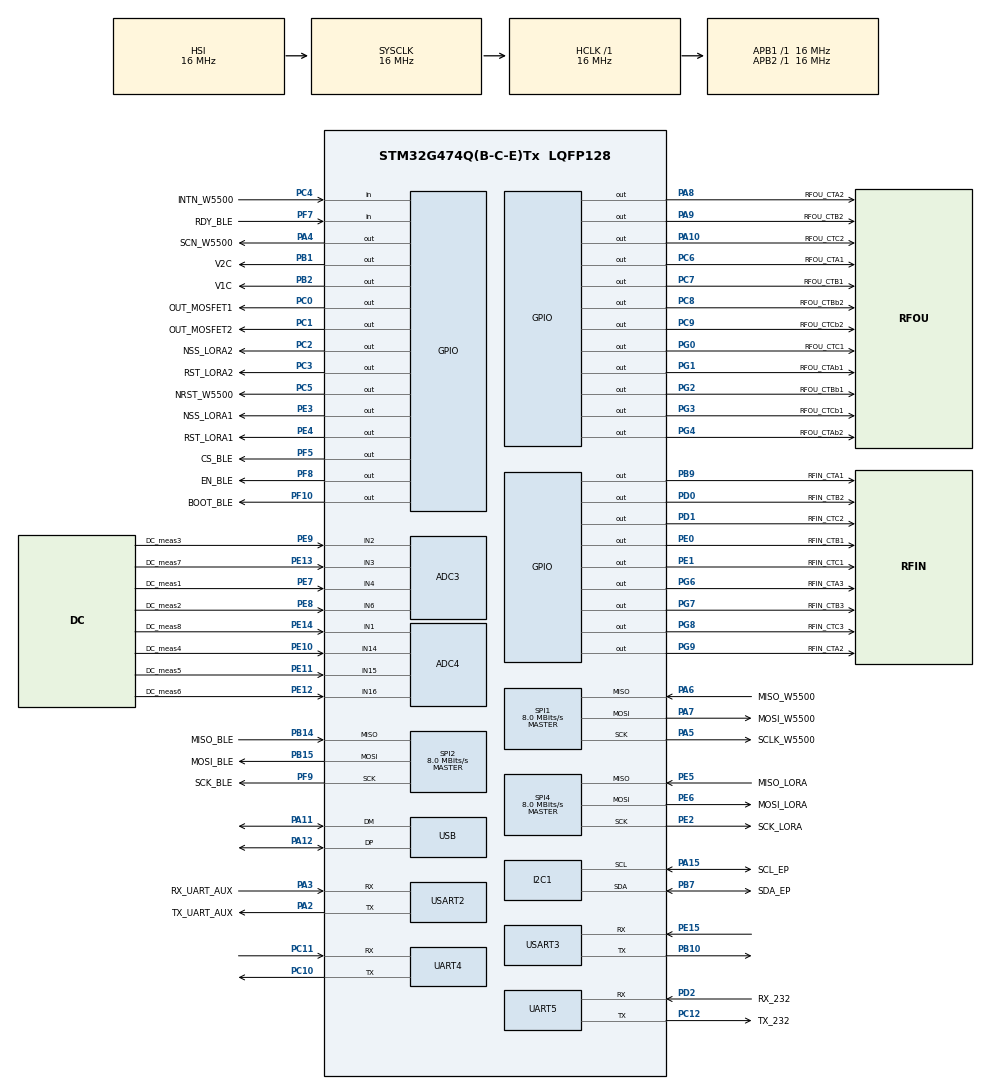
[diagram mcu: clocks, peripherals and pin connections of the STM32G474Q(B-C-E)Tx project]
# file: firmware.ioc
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ADC3.Channel-0\#ChannelRegularConversion=ADC_CHANNEL_4
ADC3.NbrOfConversionFlag=1
ADC3.OffsetNumber-0\#ChannelRegularConversion=ADC_OFFSET_NONE
ADC3.Rank-0\#ChannelRegularConversion=1
ADC3.SamplingTime-0\#ChannelRegularConversion=ADC_SAMPLETIME_2CYCLES_5
ADC3.master=1
ADC4.Channel-0\#ChannelRegularConversion=ADC_CHANNEL_1
ADC4.NbrOfConversionFlag=1
ADC4.OffsetNumber-0\#ChannelRegularConversion=ADC_OFFSET_NONE
ADC4.Rank-0\#ChannelRegularConversion=1
ADC4.SamplingTime-0\#ChannelRegularConversion=ADC_SAMPLETIME_2CYCLES_5
I2C1.Timing=0x00503D58
Mcu.Family=STM32G4
Mcu.Name=STM32G474Q(B-C-E)Tx
Mcu.Package=LQFP128
NVIC.PriorityGroup=NVIC_PRIORITYGROUP_4
NVIC.UART4_IRQn=true\:0\:0\:false\:false\:true\:true\:true\:true
NVIC.UART5_IRQn=true\:0\:0\:false\:false\:true\:true\:true\:true
NVIC.USART2_IRQn=true\:0\:0\:false\:false\:true\:true\:true\:true
NVIC.USART3_IRQn=true\:0\:0\:false\:false\:true\:true\:true\:true
NVIC.USB_LP_IRQn=true\:0\:0\:false\:false\:true\:false\:true\:true
PA10.GPIO_Label=RFOU_CTC2
PA10.Signal=GPIO_Output
PA11.Mode=Device
PA11.Signal=USB_DM
PA12.Mode=Device
PA12.Signal=USB_DP
PA15.GPIO_Label=SCL_EP
PA15.Mode=I2C
PA15.Signal=I2C1_SCL
PA2.GPIO_Label=TX_UART_AUX
PA2.Mode=Asynchronous
PA2.Signal=USART2_TX
PA3.GPIO_Label=RX_UART_AUX
PA3.Mode=Asynchronous
PA3.Signal=USART2_RX
PA4.GPIO_Label=SCN_W5500
PA4.Signal=GPIO_Output
PA5.GPIO_Label=SCLK_W5500
PA5.Mode=Full_Duplex_Master
PA5.Signal=SPI1_SCK
PA6.GPIO_Label=MISO_W5500
PA6.Mode=Full_Duplex_Master
PA6.Signal=SPI1_MISO
PA7.GPIO_Label=MOSI_W5500
PA7.Mode=Full_Duplex_Master
PA7.Signal=SPI1_MOSI
PA8.GPIO_Label=RFOU_CTA2
PA8.Signal=GPIO_Output
PA9.GPIO_Label=RFOU_CTB2
PA9.Signal=GPIO_Output
PB1.GPIO_Label=V2C
PB1.Signal=GPIO_Output
PB10.Mode=Asynchronous
PB10.Signal=USART3_TX
PB14.GPIO_Label=MISO_BLE
PB14.Mode=Full_Duplex_Master
PB14.Signal=SPI2_MISO
PB15.GPIO_Label=MOSI_BLE
PB15.Mode=Full_Duplex_Master
PB15.Signal=SPI2_MOSI
PB2.GPIO_Label=V1C
PB2.Signal=GPIO_Output
PB7.GPIO_Label=SDA_EP
PB7.Mode=I2C
PB7.Signal=I2C1_SDA
PB9.GPIO_Label=RFIN_CTA1
PB9.Signal=GPIO_Output
PC0.GPIO_Label=OUT_MOSFET1
PC0.Signal=GPIO_Output
PC1.GPIO_Label=OUT_MOSFET2
PC1.Signal=GPIO_Output
PC10.Mode=Asynchronous
PC10.Signal=UART4_TX
PC11.Mode=Asynchronous
PC11.Signal=UART4_RX
PC12.GPIO_Label=TX_232
PC12.Mode=Asynchronous
PC12.Signal=UART5_TX
PC2.GPIO_Label=NSS_LORA2
PC2.Signal=GPIO_Output
PC3.GPIO_Label=RST_LORA2
PC3.Signal=GPIO_Output
PC4.GPIO_Label=INTN_W5500
PC4.Signal=GPIO_Input
PC5.GPIO_Label=NRST_W5500
PC5.Signal=GPIO_Output
PC6.GPIO_Label=RFOU_CTA1
PC6.Signal=GPIO_Output
PC7.GPIO_Label=RFOU_CTB1
PC7.Signal=GPIO_Output
PC8.GPIO_Label=RFOU_CTBb2
PC8.Signal=GPIO_Output
PC9.GPIO_Label=RFOU_CTCb2
PC9.Signal=GPIO_Output
PD0.GPIO_Label=RFIN_CTB2
PD0.Signal=GPIO_Output
PD1.GPIO_Label=RFIN_CTC2
PD1.Signal=GPIO_Output
PD2.GPIO_Label=RX_232
PD2.Mode=Asynchronous
PD2.Signal=UART5_RX
PE0.GPIO_Label=RFIN_CTB1
PE0.Signal=GPIO_Output
PE1.GPIO_Label=RFIN_CTC1
PE1.Signal=GPIO_Output
PE10.GPIO_Label=DC_meas4
PE10.Signal=SharedAnalog_PE10
PE11.GPIO_Label=DC_meas5
PE11.Signal=SharedAnalog_PE11
PE12.GPIO_Label=DC_meas6
PE12.Signal=SharedAnalog_PE12
PE13.GPIO_Label=DC_meas7
PE13.Signal=SharedAnalog_PE13
PE14.GPIO_Label=DC_meas8
PE14.Signal=SharedAnalog_PE14
PE15.Mode=Asynchronous
PE15.Signal=USART3_RX
PE2.GPIO_Label=SCK_LORA
PE2.Mode=Full_Duplex_Master
PE2.Signal=SPI4_SCK
PE3.GPIO_Label=NSS_LORA1
PE3.Signal=GPIO_Output
PE4.GPIO_Label=RST_LORA1
PE4.Signal=GPIO_Output
PE5.GPIO_Label=MISO_LORA
PE5.Mode=Full_Duplex_Master
PE5.Signal=SPI4_MISO
PE6.GPIO_Label=MOSI_LORA
PE6.Mode=Full_Duplex_Master
PE6.Signal=SPI4_MOSI
PE7.GPIO_Label=DC_meas1
PE7.Signal=SharedAnalog_PE7
PE8.GPIO_Label=DC_meas2
PE8.Signal=SharedAnalog_PE8
PE9.GPIO_Label=DC_meas3
PE9.Signal=SharedAnalog_PE9
PF10.GPIO_Label=BOOT_BLE
PF10.Signal=GPIO_Output
PF5.GPIO_Label=CS_BLE
PF5.Signal=GPIO_Output
PF7.GPIO_Label=RDY_BLE
PF7.Signal=GPIO_Input
PF8.GPIO_Label=EN_BLE
PF8.Signal=GPIO_Output
PF9.GPIO_Label=SCK_BLE
PF9.Mode=Full_Duplex_Master
PF9.Signal=SPI2_SCK
PG0.GPIO_Label=RFOU_CTC1
PG0.Signal=GPIO_Output
PG1.GPIO_Label=RFOU_CTAb1
PG1.Signal=GPIO_Output
PG2.GPIO_Label=RFOU_CTBb1
PG2.Signal=GPIO_Output
PG3.GPIO_Label=RFOU_CTCb1
PG3.Signal=GPIO_Output
PG4.GPIO_Label=RFOU_CTAb2
PG4.Signal=GPIO_Output
PG6.GPIO_Label=RFIN_CTA3
PG6.Signal=GPIO_Output
PG7.GPIO_Label=RFIN_CTB3
PG7.Signal=GPIO_Output
PG8.GPIO_Label=RFIN_CTC3
PG8.Signal=GPIO_Output
PG9.GPIO_Label=RFIN_CTA2
PG9.Signal=GPIO_Output
ProjectManager.HeapSize=0x200
ProjectManager.StackSize=0x400
ProjectManager.TargetToolchain=CMake
RCC.AHBFreq_Value=16000000
RCC.APB1Freq_Value=16000000
RCC.APB1TimFreq_Value=16000000
RCC.APB2Freq_Value=16000000
RCC.APB2TimFreq_Value=16000000
RCC.CortexFreq_Value=16000000
RCC.EXTERNAL_CLOCK_VALUE=12288000
RCC.HCLKFreq_Value=16000000
RCC.HSE_VALUE=8000000
RCC.HSI48_VALUE=48000000
RCC.HSI_VALUE=16000000
RCC.LSE_VALUE=32768
RCC.PLLN=12
RCC.PLLQ=RCC_PLLQ_DIV4
RCC.SYSCLKFreq_VALUE=16000000
RCC.USBFreq_Value=48000000
RCC.VCOOutputFreq_Value=192000000
SH.SharedAnalog_PE10.0=GPIO_Analog
SH.SharedAnalog_PE10.1=ADC4_IN14,IN14-Single-Ended
SH.SharedAnalog_PE11.0=GPIO_Analog
SH.SharedAnalog_PE11.1=ADC4_IN15,IN15-Single-Ended
SH.SharedAnalog_PE12.0=GPIO_Analog
SH.SharedAnalog_PE12.1=ADC4_IN16,IN16-Single-Ended
SH.SharedAnalog_PE13.0=GPIO_Analog
SH.SharedAnalog_PE13.1=ADC3_IN3,IN3-Single-Ended
SH.SharedAnalog_PE14.0=GPIO_Analog
SH.SharedAnalog_PE14.1=ADC4_IN1,IN1-Single-Ended
SH.SharedAnalog_PE7.0=GPIO_Analog
SH.SharedAnalog_PE7.1=ADC3_IN4,IN4-Single-Ended
SH.SharedAnalog_PE8.0=GPIO_Analog
SH.SharedAnalog_PE8.1=ADC3_IN6,IN6-Single-Ended
SH.SharedAnalog_PE9.0=GPIO_Analog
SH.SharedAnalog_PE9.1=ADC3_IN2,IN2-Single-Ended
SPI1.CalculateBaudRate=8.0 MBits/s
SPI1.Direction=SPI_DIRECTION_2LINES
SPI1.Mode=SPI_MODE_MASTER
SPI1.VirtualType=VM_MASTER
SPI2.CalculateBaudRate=8.0 MBits/s
SPI2.Direction=SPI_DIRECTION_2LINES
SPI2.Mode=SPI_MODE_MASTER
SPI2.VirtualType=VM_MASTER
SPI4.CalculateBaudRate=8.0 MBits/s
SPI4.Direction=SPI_DIRECTION_2LINES
SPI4.Mode=SPI_MODE_MASTER
SPI4.VirtualType=VM_MASTER
USART2.VirtualMode-Asynchronous=VM_ASYNC
USART3.VirtualMode-Asynchronous=VM_ASYNC
USB_DEVICE.CLASS_NAME_FS=CDC
USB_DEVICE.VirtualMode=Cdc
USB_DEVICE.VirtualModeFS=Cdc_FS
VP_SYS_VS_DBSignals.Mode=DisableDeadBatterySignals
VP_USB_DEVICE_VS_USB_DEVICE_CDC_FS.Mode=CDC_FS
board=custom

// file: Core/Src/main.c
/* USER CODE BEGIN Header */
/**
  ******************************************************************************
  * @file           : main.c
  * @brief          : Main program body
  ******************************************************************************
  * @attention
  *
  * Copyright (c) 2026 STMicroelectronics.
  * All rights reserved.
  *
  * This software is licensed under terms that can be found in the LICENSE file
  * in the root directory of this software component.
  * If no LICENSE file comes with this software, it is provided AS-IS.
  *
  ******************************************************************************
  */
/* USER CODE END Header */
#include "main.h"
#include "adc.h"
#include "i2c.h"
#include "spi.h"
#include "usart.h"
#include "usb_device.h"
#include "gpio.h"

/* USER CODE BEGIN Includes */
#include <string.h>   /* strlen() para los mensajes */
/* USER CODE END Includes */

/* USER CODE BEGIN PD */

/* W5500 Network Configuration */
#define W5500_SOCKET        0

/* MAC Address: 02:00:00:00:00:01 */
#define W5500_MAC0          0x02
#define W5500_MAC1          0x00
#define W5500_MAC2          0x00
#define W5500_MAC3          0x00
#define W5500_MAC4          0x00
#define W5500_MAC5          0x01

/* Static IP: 192.168.1.50 */
#define W5500_IP0           192
#define W5500_IP1           168
#define W5500_IP2           1
#define W5500_IP3           50

/* Subnet Mask: 255.255.255.0 */
#define W5500_SN0           255
#define W5500_SN1           255
#define W5500_SN2           255
#define W5500_SN3           0

/* Gateway: 192.168.1.1 */
#define W5500_GW0           192
#define W5500_GW1           168
#define W5500_GW2           1
#define W5500_GW3           1

/* PC / Destination IP: 192.168.1.10 */
#define PC_IP0              192
#define PC_IP1              168
#define PC_IP2              1
#define PC_IP3              10

#define UDP_PORT            5000
#define TX_INTERVAL_MS      10000   /* envio de "KA" cada 10 segundos */

/* USER CODE END PD */

/* USER CODE BEGIN PV */
/* Variables de estado (se leen por SWD con STM32_Programmer para depurar) */
volatile uint8_t  g_ver      = 0;   /* VERSIONR: debe ser 0x04 */
volatile uint8_t  g_phy      = 0;   /* PHYCFGR: link / velocidad / duplex */
volatile uint8_t  g_socket   = 0;   /* estado del socket (0x22 = UDP) */
volatile uint8_t  g_snmr     = 0;   /* protocolo del socket (0x02 = UDP) */
volatile uint8_t  g_phy_live = 0;   /* PHYCFGR leido en el bucle */
volatile uint16_t g_rsr      = 0;   /* bytes recibidos pendientes */
volatile uint16_t g_tx_count = 0;   /* mensajes enviados */
volatile uint16_t g_rx_count = 0;   /* mensajes recibidos */
/* USER CODE END PV */

void SystemClock_Config(void);

/* USER CODE BEGIN 0 */

/* ------------------------------------------------------------------
 * W5500: bloques de registros
 * ------------------------------------------------------------------ */
#define COMMON_BLOCK   0x00      /* registros comunes (MAC, IP, PHY...) */
#define SOCK0_BLOCK    0x01      /* registros del socket 0 */
#define SOCK0_TXBUF    0x02      /* buffer de transmision del socket 0 */
#define SOCK0_RXBUF    0x03      /* buffer de recepcion del socket 0 */

/* Registros comunes (bloque 0) */
#define MR             0x0000    /* modo */
#define SHAR           0x0009    /* direccion MAC (6 bytes) */
#define GAR            0x0001    /* gateway (4 bytes) */
#define SUBR           0x0005    /* mascara de subred (4 bytes) */
#define SIPR           0x000F    /* IP local (4 bytes) */
#define PHYCFGR        0x002E    /* configuracion del PHY */
#define VERSIONR       0x0039    /* version del chip (debe leer 0x04) */

/* Registros del socket 0 */
#define Sn_MR          0x0000    /* protocolo (0x02 = UDP) */
#define Sn_CR          0x0001    /* comando */
#define Sn_SR          0x0003    /* estado */
#define Sn_PORT        0x0004    /* puerto local (2 bytes) */
#define Sn_DIPR        0x000C    /* IP destino (4 bytes) */
#define Sn_DPORT       0x0010    /* puerto destino (2 bytes) */
#define Sn_RXBUF_SIZE  0x001E    /* tamanio del buffer RX (en KB) */
#define Sn_TXBUF_SIZE  0x001F    /* tamanio del buffer TX (en KB) */
#define Sn_TX_FSR      0x0020    /* espacio libre en TX */
#define Sn_TX_WR       0x0024    /* puntero de escritura de TX */
#define Sn_RX_RSR      0x0026    /* bytes recibidos pendientes */
#define Sn_RX_RD       0x0028    /* puntero de lectura de RX */

/* Comandos (Sn_CR) */
#define CR_OPEN        0x01      /* abrir socket */
#define CR_SEND        0x20      /* enviar */
#define CR_RECV        0x40      /* confirmar recepcion */

/* Estado del socket */
#define SOCK_UDP       0x22      /* socket abierto en modo UDP */

/* ------- Funciones de bajo nivel (SPI) ------- */
static void     w5500_hw_reset(void);
static void     w5500_write_reg(uint16_t addr, uint8_t block, uint8_t data);
static uint8_t  w5500_read_reg(uint16_t addr, uint8_t block);
static void     w5500_write_reg16(uint16_t addr, uint8_t block, uint16_t val);
static uint16_t w5500_read_reg16(uint16_t addr, uint8_t block);
static void     w5500_write_buf(uint8_t block, uint16_t addr, uint8_t* data, uint16_t len);
static void     w5500_read_buf(uint8_t block, uint16_t addr, uint8_t* data, uint16_t len);

/* ------- Funciones de aplicacion ------- */
static void udp_send(const char* msg);   /* envia un mensaje UDP al destino actual */

/* USER CODE END 0 */

int main(void)
{

  /* MCU Configuration--------------------------------------------------------*/

  /* Reset of all peripherals, Initializes the Flash interface and the Systick. */
  HAL_Init();

  /* Configure the system clock */
  SystemClock_Config();

  /* Initialize all configured peripherals */
  MX_GPIO_Init();
  MX_UART5_Init();
  MX_USART2_UART_Init();
  MX_ADC3_Init();
  MX_ADC4_Init();
  MX_I2C1_Init();
  MX_SPI1_Init();
  MX_SPI2_Init();
  MX_SPI4_Init();
  MX_UART4_Init();
  MX_USART3_UART_Init();
  /* USB CDC deshabilitado durante debug (colgaba en ISR USB_LP). Se usa SWD. */
  /* MX_USB_Device_Init(); */
  /* USER CODE BEGIN 2 */

  /* ================================================================
   * 1. Reset del W5500 y verificacion del chip
   * ================================================================ */
  w5500_hw_reset();                          /* reset por el pin NRST */
  w5500_write_reg(MR, COMMON_BLOCK, 0x80);   /* reset por software */
  HAL_Delay(100);
  w5500_write_reg(MR, COMMON_BLOCK, 0x00);   /* modo normal */

  g_ver = w5500_read_reg(VERSIONR, COMMON_BLOCK);
  if (g_ver != 0x04) {                       /* el chip debe leer 0x04 */
      while (1) { HAL_Delay(1000); }         /* W5500 no responde */
  }

  /* ================================================================
   * 2. Configuracion de red (MAC, IP, mascara, gateway)
   * ================================================================ */
  {
      uint8_t mac[6] = {W5500_MAC0, W5500_MAC1, W5500_MAC2,
                        W5500_MAC3, W5500_MAC4, W5500_MAC5};
      uint8_t ip[4]  = {W5500_IP0, W5500_IP1, W5500_IP2, W5500_IP3};
      uint8_t sn[4]  = {W5500_SN0, W5500_SN1, W5500_SN2, W5500_SN3};
      uint8_t gw[4]  = {W5500_GW0, W5500_GW1, W5500_GW2, W5500_GW3};
      int i;
      for (i = 0; i < 6; i++) w5500_write_reg(SHAR + i, COMMON_BLOCK, mac[i]);
      for (i = 0; i < 4; i++) w5500_write_reg(SIPR + i, COMMON_BLOCK, ip[i]);
      for (i = 0; i < 4; i++) w5500_write_reg(SUBR + i, COMMON_BLOCK, sn[i]);
      for (i = 0; i < 4; i++) w5500_write_reg(GAR  + i, COMMON_BLOCK, gw[i]);
  }

  /* ================================================================
   * 3. PHY: auto-negociacion y espera del link
   * ================================================================ */
  w5500_write_reg(PHYCFGR, COMMON_BLOCK, 0xF8);   /* RST=1, auto-neg, todo capaz */
  HAL_Delay(1);
  w5500_write_reg(PHYCFGR, COMMON_BLOCK, 0x78);   /* RST=0 -> reset del PHY */
  HAL_Delay(1);
  w5500_write_reg(PHYCFGR, COMMON_BLOCK, 0xF8);   /* RST=1 -> liberar reset */

  {
      uint32_t t = 0;
      while (t < 3000) {                          /* esperar link (max ~3 s) */
          if (w5500_read_reg(PHYCFGR, COMMON_BLOCK) & 0x01) break;  /* LNK=1 */
          HAL_Delay(10);
          t += 10;
      }
  }
  g_phy = w5500_read_reg(PHYCFGR, COMMON_BLOCK);

  /* ================================================================
   * 4. Socket 0 en modo UDP, puerto 5000
   * ================================================================ */
  w5500_write_reg(Sn_RXBUF_SIZE, SOCK0_BLOCK, 2);   /* 2 KB de RX */
  w5500_write_reg(Sn_TXBUF_SIZE, SOCK0_BLOCK, 2);   /* 2 KB de TX */
  w5500_write_reg(Sn_MR, SOCK0_BLOCK, 0x02);        /* 0x02 = UDP */
  w5500_write_reg16(Sn_PORT, SOCK0_BLOCK, UDP_PORT);
  w5500_write_reg(Sn_CR, SOCK0_BLOCK, CR_OPEN);     /* abrir el socket */
  HAL_Delay(10);
  g_snmr   = w5500_read_reg(Sn_MR, SOCK0_BLOCK);    /* debe leer 0x02 */
  g_socket = w5500_read_reg(Sn_SR, SOCK0_BLOCK);    /* debe leer 0x22 (UDP) */

  /* ================================================================
   * 5. Bucle principal
   *      (a) Si llega un mensaje UDP -> responde "RECIBIDO".
   *      (b) Cada 10 s -> envia "KA" al PC.
   * ================================================================ */
  {
      uint8_t  rx[128];
      uint32_t last_tick = HAL_GetTick();

      while (1)
      {
          /* --- (a) Recepcion --- */
          g_rsr = w5500_read_reg16(Sn_RX_RSR, SOCK0_BLOCK);
          if (g_rsr >= 1)
          {
              uint16_t n    = g_rsr;
              uint16_t rxrd = w5500_read_reg16(Sn_RX_RD, SOCK0_BLOCK);
              if (n > sizeof(rx)) n = sizeof(rx);

              w5500_read_buf(SOCK0_RXBUF, rxrd, rx, n);
              w5500_write_reg16(Sn_RX_RD, SOCK0_BLOCK, rxrd + n);
              w5500_write_reg(Sn_CR, SOCK0_BLOCK, CR_RECV);
              g_rx_count++;

              /* El W5500 ya guardo en Sn_DIPR/Sn_DPORT la IP y puerto
               * del emisor, por eso udp_send() responde al emisor. */
              udp_send("RECIBIDO");
          }

          /* --- (b) Keep-alive cada 10 s --- */
          if (HAL_GetTick() - last_tick >= TX_INTERVAL_MS)
          {
              last_tick = HAL_GetTick();

              /* destino = broadcast (255.255.255.255 : 5000).
               * Se usa broadcast (no unicast al PC) porque el unicast
               * necesita ARP para resolver la MAC del PC, y el RX del
               * W5500 esta fallando: nunca recibe la respuesta ARP, por
               * lo que el paquete UDP jamas se envia. El broadcast no
               * necesita ARP y sale directo por TX. */
              w5500_write_reg(Sn_DIPR + 0, SOCK0_BLOCK, 255);
              w5500_write_reg(Sn_DIPR + 1, SOCK0_BLOCK, 255);
              w5500_write_reg(Sn_DIPR + 2, SOCK0_BLOCK, 255);
              w5500_write_reg(Sn_DIPR + 3, SOCK0_BLOCK, 255);
              w5500_write_reg16(Sn_DPORT, SOCK0_BLOCK, UDP_PORT);

              udp_send("KA");
          }

          /* estado vivo para debug por SWD */
          g_phy_live = w5500_read_reg(PHYCFGR, COMMON_BLOCK);
          g_socket   = w5500_read_reg(Sn_SR, SOCK0_BLOCK);

          HAL_Delay(5);
      }
  }

  /* USER CODE END 2 */

  /* Infinite loop */
  while (1)
  {

  }
}

void SystemClock_Config(void)
{
  RCC_OscInitTypeDef RCC_OscInitStruct = {0};
  RCC_ClkInitTypeDef RCC_ClkInitStruct = {0};

  /** Configure the main internal regulator output voltage
  */
  HAL_PWREx_ControlVoltageScaling(PWR_REGULATOR_VOLTAGE_SCALE1);

  /** Initializes the RCC Oscillators according to the specified parameters
  * in the RCC_OscInitTypeDef structure.
  */
  RCC_OscInitStruct.OscillatorType = RCC_OSCILLATORTYPE_HSI;
  RCC_OscInitStruct.HSIState = RCC_HSI_ON;
  RCC_OscInitStruct.HSICalibrationValue = RCC_HSICALIBRATION_DEFAULT;
  RCC_OscInitStruct.PLL.PLLState = RCC_PLL_ON;
  RCC_OscInitStruct.PLL.PLLSource = RCC_PLLSOURCE_HSI;
  RCC_OscInitStruct.PLL.PLLM = RCC_PLLM_DIV1;
  RCC_OscInitStruct.PLL.PLLN = 12;
  RCC_OscInitStruct.PLL.PLLP = RCC_PLLP_DIV2;
  RCC_OscInitStruct.PLL.PLLQ = RCC_PLLQ_DIV4;
  RCC_OscInitStruct.PLL.PLLR = RCC_PLLR_DIV2;
  if (HAL_RCC_OscConfig(&RCC_OscInitStruct) != HAL_OK)
  {
    Error_Handler();
  }

  /** Initializes the CPU, AHB and APB buses clocks
  */
  RCC_ClkInitStruct.ClockType = RCC_CLOCKTYPE_HCLK|RCC_CLOCKTYPE_SYSCLK
                              |RCC_CLOCKTYPE_PCLK1|RCC_CLOCKTYPE_PCLK2;
  RCC_ClkInitStruct.SYSCLKSource = RCC_SYSCLKSOURCE_HSI;
  RCC_ClkInitStruct.AHBCLKDivider = RCC_SYSCLK_DIV1;
  RCC_ClkInitStruct.APB1CLKDivider = RCC_HCLK_DIV1;
  RCC_ClkInitStruct.APB2CLKDivider = RCC_HCLK_DIV1;

  if (HAL_RCC_ClockConfig(&RCC_ClkInitStruct, FLASH_LATENCY_0) != HAL_OK)
  {
    Error_Handler();
  }
}

/* USER CODE BEGIN 4 */

/* Envia un mensaje UDP por el socket 0.
 * ATENCION: el destino (Sn_DIPR / Sn_DPORT) debe estar seteado antes:
 *   - Para "KA"      -> se fija la IP del PC antes de llamar.
 *   - Para "RECIBIDO" -> el W5500 ya guardo el origen al recibir. */
static void udp_send(const char* msg)
{
    uint16_t len  = (uint16_t)strlen(msg);
    uint16_t txwr;

    /* esperar espacio libre en el buffer de transmision */
    while (w5500_read_reg16(Sn_TX_FSR, SOCK0_BLOCK) < len) {
        HAL_Delay(1);
    }

    /* escribir el mensaje y avanzar el puntero de escritura */
    txwr = w5500_read_reg16(Sn_TX_WR, SOCK0_BLOCK);
    w5500_write_buf(SOCK0_TXBUF, txwr, (uint8_t*)msg, len);
    w5500_write_reg16(Sn_TX_WR, SOCK0_BLOCK, txwr + len);

    /* ordenar el envio */
    w5500_write_reg(Sn_CR, SOCK0_BLOCK, CR_SEND);
    g_tx_count++;
}

static void w5500_hw_reset(void)
{
    HAL_GPIO_WritePin(NRST_W5500_GPIO_Port, NRST_W5500_Pin, GPIO_PIN_RESET);
    HAL_Delay(10);
    HAL_GPIO_WritePin(NRST_W5500_GPIO_Port, NRST_W5500_Pin, GPIO_PIN_SET);
    HAL_Delay(10);
}

static void w5500_write_reg(uint16_t addr, uint8_t block, uint8_t data)
{
    uint8_t cmd[4];
    cmd[0] = (addr >> 8) & 0xFF;
    cmd[1] = addr & 0xFF;
    cmd[2] = (block << 3) | (1 << 2) | 0x00;
    cmd[3] = data;
    HAL_GPIO_WritePin(SCN_W5500_GPIO_Port, SCN_W5500_Pin, GPIO_PIN_RESET);
    HAL_SPI_Transmit(&hspi1, cmd, 4, HAL_MAX_DELAY);
    HAL_GPIO_WritePin(SCN_W5500_GPIO_Port, SCN_W5500_Pin, GPIO_PIN_SET);
}

static uint8_t w5500_read_reg(uint16_t addr, uint8_t block)
{
    uint8_t cmd[4];
    cmd[0] = (addr >> 8) & 0xFF;
    cmd[1] = addr & 0xFF;
    cmd[2] = ((block << 3) & 0xF8) | (0 << 2) | 0x00;
    cmd[3] = 0;
    HAL_GPIO_WritePin(SCN_W5500_GPIO_Port, SCN_W5500_Pin, GPIO_PIN_RESET);
    HAL_StatusTypeDef st1 = HAL_SPI_Transmit(&hspi1, cmd, 3, 2000);
    HAL_StatusTypeDef st2 = HAL_SPI_Receive(&hspi1, &cmd[3], 1, 2000);
    HAL_GPIO_WritePin(SCN_W5500_GPIO_Port, SCN_W5500_Pin, GPIO_PIN_SET);
    if (st1 == HAL_OK && st2 == HAL_OK) return cmd[3];
    return 0;
}

static void w5500_write_reg16(uint16_t addr, uint8_t block, uint16_t val)
{
    w5500_write_reg(addr,     block, (uint8_t)(val >> 8));
    w5500_write_reg(addr + 1, block, (uint8_t)(val & 0xFF));
}

static uint16_t w5500_read_reg16(uint16_t addr, uint8_t block)
{
    uint16_t hi = w5500_read_reg(addr,     block);
    uint16_t lo = w5500_read_reg(addr + 1, block);
    return (hi << 8) | lo;
}

static void w5500_write_buf(uint8_t block, uint16_t addr, uint8_t* data, uint16_t len)
{
    uint8_t hdr[3];
    hdr[0] = (addr >> 8) & 0xFF;
    hdr[1] = addr & 0xFF;
    hdr[2] = (block << 3) | (1 << 2) | 0x00;  /* write, VDM */
    HAL_GPIO_WritePin(SCN_W5500_GPIO_Port, SCN_W5500_Pin, GPIO_PIN_RESET);
    HAL_SPI_Transmit(&hspi1, hdr, 3, HAL_MAX_DELAY);
    HAL_SPI_Transmit(&hspi1, data, len, HAL_MAX_DELAY);
    HAL_GPIO_WritePin(SCN_W5500_GPIO_Port, SCN_W5500_Pin, GPIO_PIN_SET);
}

static void w5500_read_buf(uint8_t block, uint16_t addr, uint8_t* data, uint16_t len)
{
    uint8_t hdr[3];
    hdr[0] = (addr >> 8) & 0xFF;
    hdr[1] = addr & 0xFF;
    hdr[2] = ((block << 3) & 0xF8) | (0 << 2) | 0x00;  /* read, VDM */
    HAL_GPIO_WritePin(SCN_W5500_GPIO_Port, SCN_W5500_Pin, GPIO_PIN_RESET);
    HAL_SPI_Transmit(&hspi1, hdr, 3, HAL_MAX_DELAY);
    HAL_SPI_Receive(&hspi1, data, len, HAL_MAX_DELAY);
    HAL_GPIO_WritePin(SCN_W5500_GPIO_Port, SCN_W5500_Pin, GPIO_PIN_SET);
}

/* USER CODE END 4 */

void Error_Handler(void)
{
  __disable_irq();
  while (1)
  {
  }
}
